# iosam3n register map
Registers are 32-bit, access not given, no defined reset value unless marked. A register's access mark holds for its fields unless they carry their own. Addresses are absolute; registers are grouped by the start of their names; [hi:lo] are bit positions; {n}, {i} and the like mark numbered series; 'fields as' and 'values as' point back to an identical list.

## ADC
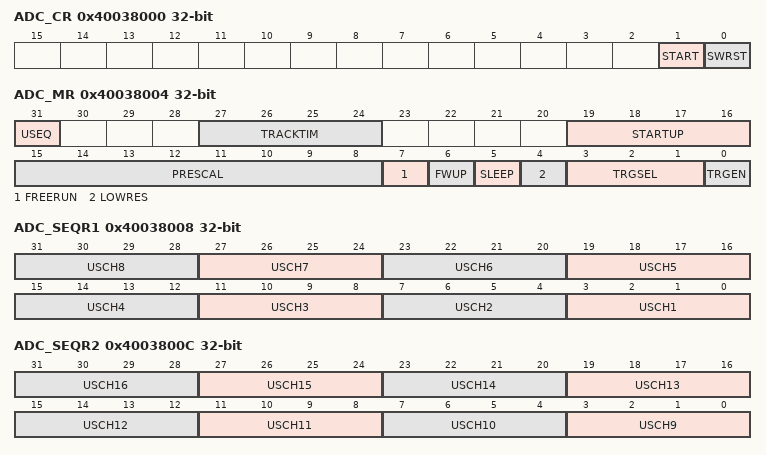
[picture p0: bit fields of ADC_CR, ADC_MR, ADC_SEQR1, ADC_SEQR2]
0x40038000 ADC_CR
  [1] START, [0] SWRST
0x40038004 ADC_MR
  [31] USEQ, [27:24] TRACKTIM, [19:16] STARTUP, [15:8] PRESCAL, [7] FREERUN, [6] FWUP, [5] SLEEP, [4] LOWRES, [3:1] TRGSEL, [0] TRGEN
0x40038008 ADC_SEQR1
  [4n-1:4n-4] USCH{n} (n=1..8)
0x4003800C ADC_SEQR2
  [4n-33:4n-36] USCH{n} (n=9..16)
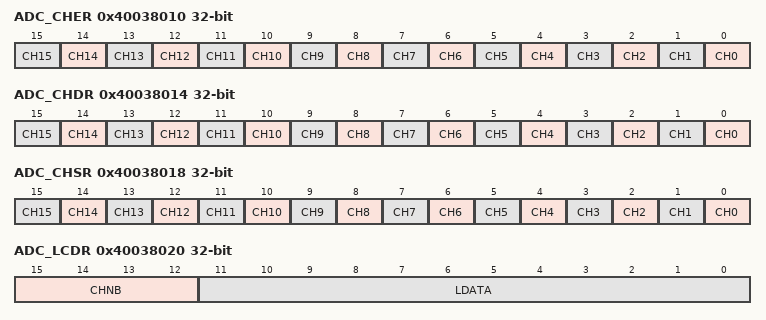
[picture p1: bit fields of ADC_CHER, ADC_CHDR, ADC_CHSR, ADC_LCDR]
0x40038010 ADC_CHER
  [n] CH{n} (n=0..15)
0x40038014 ADC_CHDR
  [n] CH{n} (n=0..15)
0x40038018 ADC_CHSR
  [n] CH{n} (n=0..15)
0x40038020 ADC_LCDR
  [15:12] CHNB, [11:0] LDATA
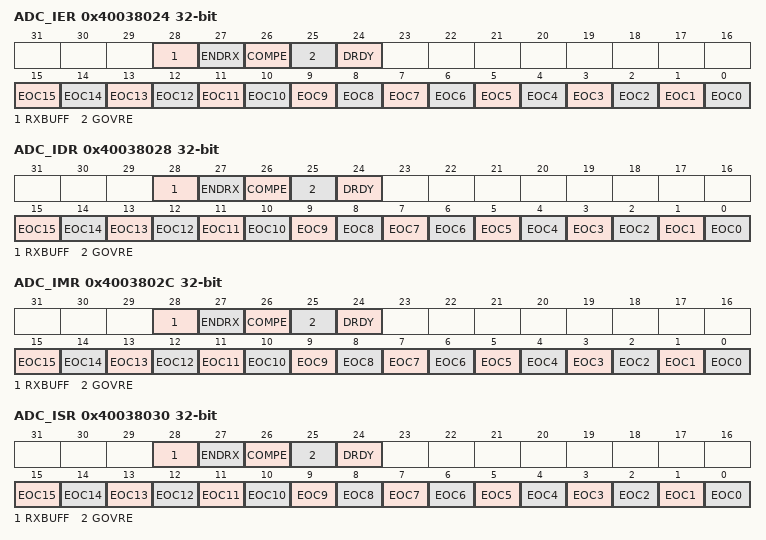
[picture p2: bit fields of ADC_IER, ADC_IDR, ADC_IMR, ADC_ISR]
0x40038024 ADC_IER
  [28] RXBUFF, [27] ENDRX, [26] COMPE, [25] GOVRE, [24] DRDY, [n] EOC{n} (n=0..15)
0x40038028 ADC_IDR
  fields as ADC_IER
0x4003802C ADC_IMR
  fields as ADC_IER
0x40038030 ADC_ISR
  fields as ADC_IER
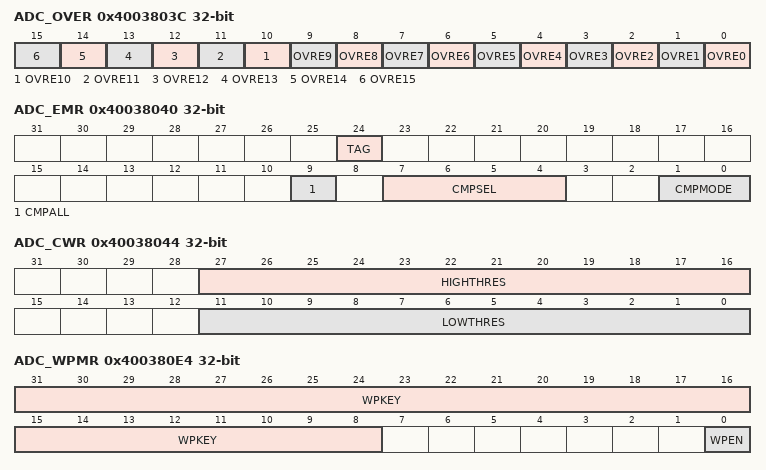
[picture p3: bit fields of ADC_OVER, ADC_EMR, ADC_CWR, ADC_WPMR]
0x4003803C ADC_OVER
  [n] OVRE{n} (n=0..15)
0x40038040 ADC_EMR
  [24] TAG, [9] CMPALL, [7:4] CMPSEL, [1:0] CMPMODE
0x40038044 ADC_CWR
  [27:16] HIGHTHRES, [11:0] LOWTHRES
{0x40038050+4i} ADC_CDR_{i} (i=0..15)
  [9:0] DATA
0x400380E4 ADC_WPMR
  [31:8] WPKEY, [0] WPEN
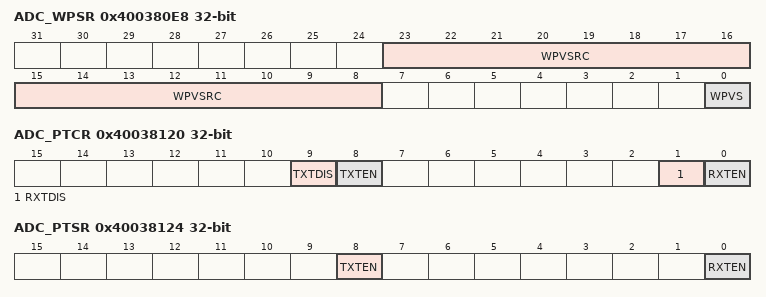
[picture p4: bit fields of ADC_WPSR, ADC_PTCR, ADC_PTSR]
0x400380E8 ADC_WPSR
  [23:8] WPVSRC, [0] WPVS
0x40038100 ADC_RPR
  [31:0] RXPTR
0x40038104 ADC_RCR
  [15:0] RXCTR
0x40038108 ADC_TPR
  [31:0] TXPTR
0x4003810C ADC_TCR
  [15:0] TXCTR
0x40038110 ADC_RNPR
  [31:0] RXNPTR
0x40038114 ADC_RNCR
  [15:0] RXNCTR
0x40038118 ADC_TNPR
  [31:0] TXNPTR
0x4003811C ADC_TNCR
  [15:0] TXNCTR
0x40038120 ADC_PTCR
  [9] TXTDIS, [8] TXTEN, [1] RXTDIS, [0] RXTEN
0x40038124 ADC_PTSR
  [8] TXTEN, [0] RXTEN

## DACC
0x4003C000 DACC_CR
  [0] SWRST
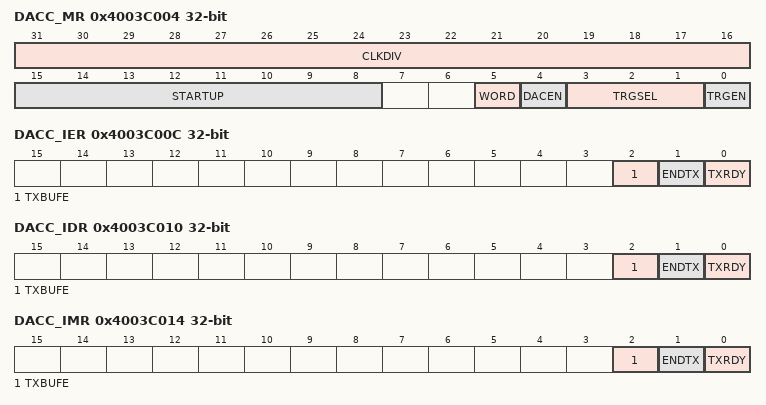
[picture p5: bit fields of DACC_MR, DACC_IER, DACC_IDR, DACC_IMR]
0x4003C004 DACC_MR
  [31:16] CLKDIV, [15:8] STARTUP, [5] WORD, [4] DACEN, [3:1] TRGSEL, [0] TRGEN
0x4003C008 DACC_CDR
  [31:0] DATA
0x4003C00C DACC_IER
  [2] TXBUFE, [1] ENDTX, [0] TXRDY
0x4003C010 DACC_IDR
  [2] TXBUFE, [1] ENDTX, [0] TXRDY
0x4003C014 DACC_IMR
  [2] TXBUFE, [1] ENDTX, [0] TXRDY
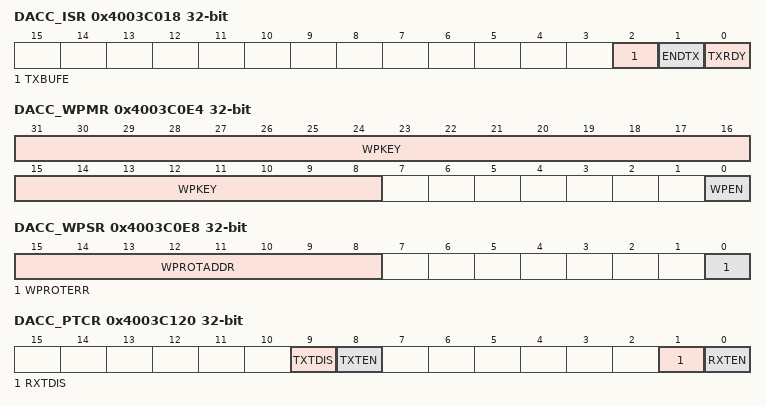
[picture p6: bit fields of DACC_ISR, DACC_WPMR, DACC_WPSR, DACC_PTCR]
0x4003C018 DACC_ISR
  [2] TXBUFE, [1] ENDTX, [0] TXRDY
0x4003C0E4 DACC_WPMR
  [31:8] WPKEY, [0] WPEN
0x4003C0E8 DACC_WPSR
  [15:8] WPROTADDR, [0] WPROTERR
0x4003C100 DACC_RPR
  [31:0] RXPTR
0x4003C104 DACC_RCR
  [15:0] RXCTR
0x4003C108 DACC_TPR
  [31:0] TXPTR
0x4003C10C DACC_TCR
  [15:0] TXCTR
0x4003C110 DACC_RNPR
  [31:0] RXNPTR
0x4003C114 DACC_RNCR
  [15:0] RXNCTR
0x4003C118 DACC_TNPR
  [31:0] TXNPTR
0x4003C11C DACC_TNCR
  [15:0] TXNCTR
0x4003C120 DACC_PTCR
  [9] TXTDIS, [8] TXTEN, [1] RXTDIS, [0] RXTEN
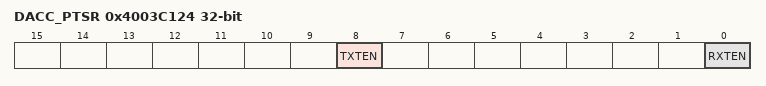
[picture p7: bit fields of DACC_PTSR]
0x4003C124 DACC_PTSR
  [8] TXTEN, [0] RXTEN

## MATRIX
{0x400E0200+4i} MATRIX_MCFG_{i} (i=0..2)
  [2:0] ULBT
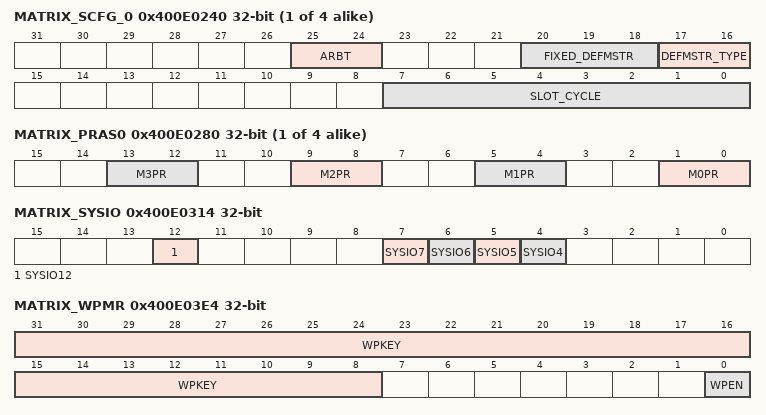
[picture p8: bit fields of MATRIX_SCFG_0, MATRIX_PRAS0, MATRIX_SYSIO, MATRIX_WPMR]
{0x400E0240+4i} MATRIX_SCFG_{i} (i=0..3)
  [25:24] ARBT, [20:18] FIXED_DEFMSTR, [17:16] DEFMSTR_TYPE, [7:0] SLOT_CYCLE
{0x400E0280+8i} MATRIX_PRAS{i} (i=0..3)
  [4n+1:4n] M{n}PR (n=0..3)
0x400E0314 MATRIX_SYSIO
  [12] SYSIO12, [n] SYSIO{n} (n=4..7)
0x400E03E4 MATRIX_WPMR
  [31:8] WPKEY, [0] WPEN
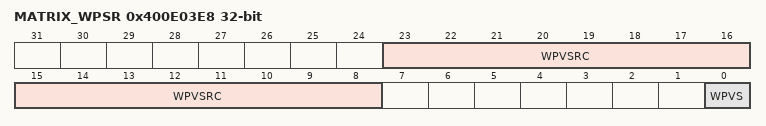
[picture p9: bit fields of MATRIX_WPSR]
0x400E03E8 MATRIX_WPSR
  [23:8] WPVSRC, [0] WPVS

## PMC
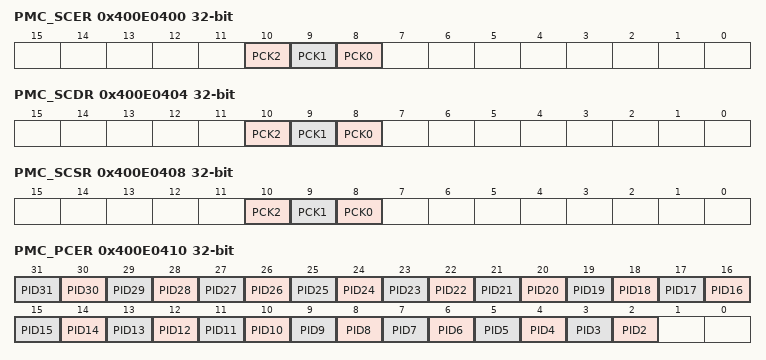
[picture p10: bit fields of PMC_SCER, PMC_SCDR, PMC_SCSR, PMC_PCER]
0x400E0400 PMC_SCER
  [10] PCK2, [9] PCK1, [8] PCK0
0x400E0404 PMC_SCDR
  [10] PCK2, [9] PCK1, [8] PCK0
0x400E0408 PMC_SCSR
  [10] PCK2, [9] PCK1, [8] PCK0
0x400E0410 PMC_PCER
  [n] PID{n} (n=2..31)
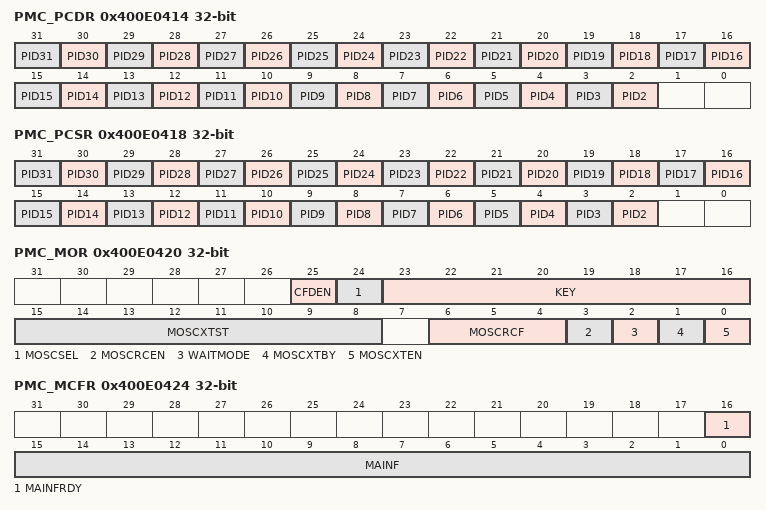
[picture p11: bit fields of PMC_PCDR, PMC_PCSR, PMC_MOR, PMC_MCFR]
0x400E0414 PMC_PCDR
  [n] PID{n} (n=2..31)
0x400E0418 PMC_PCSR
  [n] PID{n} (n=2..31)
0x400E0420 PMC_MOR
  [25] CFDEN, [24] MOSCSEL, [23:16] KEY, [15:8] MOSCXTST, [6:4] MOSCRCF, [3] MOSCRCEN, [2] WAITMODE, [1] MOSCXTBY, [0] MOSCXTEN
0x400E0424 PMC_MCFR
  [16] MAINFRDY, [15:0] MAINF
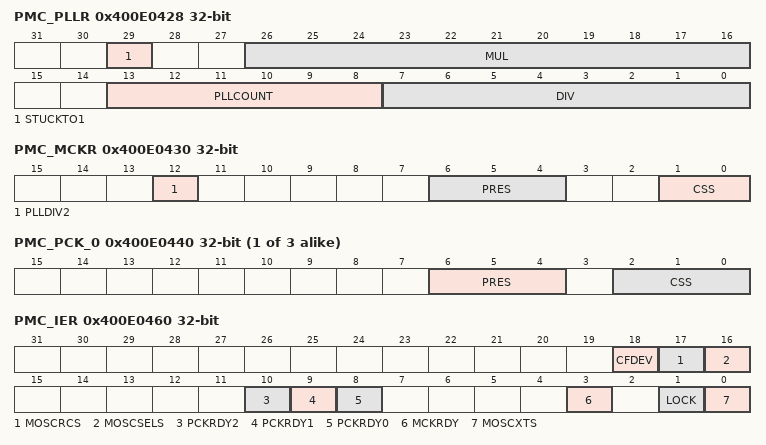
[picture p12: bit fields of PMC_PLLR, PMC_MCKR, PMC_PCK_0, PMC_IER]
0x400E0428 PMC_PLLR
  [29] STUCKTO1, [26:16] MUL, [13:8] PLLCOUNT, [7:0] DIV
0x400E0430 PMC_MCKR
  [12] PLLDIV2, [6:4] PRES, [1:0] CSS
{0x400E0440+4i} PMC_PCK_{i} (i=0..2)
  [6:4] PRES, [2:0] CSS
0x400E0460 PMC_IER
  [18] CFDEV, [17] MOSCRCS, [16] MOSCSELS, [10] PCKRDY2, [9] PCKRDY1, [8] PCKRDY0, [3] MCKRDY, [1] LOCK, [0] MOSCXTS
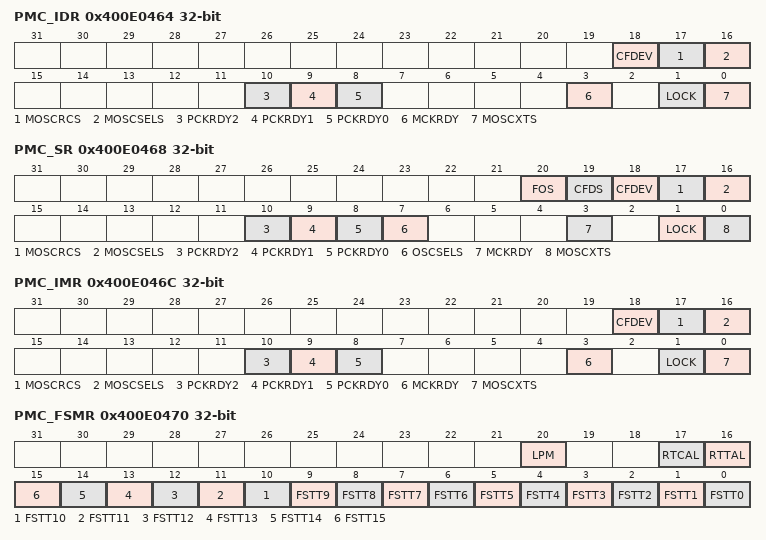
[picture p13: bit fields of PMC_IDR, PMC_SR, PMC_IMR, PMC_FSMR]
0x400E0464 PMC_IDR
  fields as PMC_IER
0x400E0468 PMC_SR
  [20] FOS, [19] CFDS, [18] CFDEV, [17] MOSCRCS, [16] MOSCSELS, [10] PCKRDY2, [9] PCKRDY1, [8] PCKRDY0, [7] OSCSELS, [3] MCKRDY, [1] LOCK, [0] MOSCXTS
0x400E046C PMC_IMR
  fields as PMC_IER
0x400E0470 PMC_FSMR
  [20] LPM, [17] RTCAL, [16] RTTAL, [n] FSTT{n} (n=0..15)
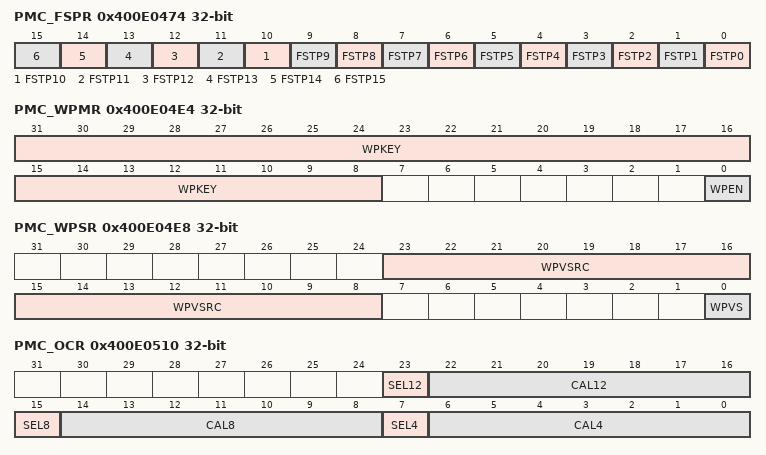
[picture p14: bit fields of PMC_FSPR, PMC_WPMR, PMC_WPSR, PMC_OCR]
0x400E0474 PMC_FSPR
  [n] FSTP{n} (n=0..15)
0x400E0478 PMC_FOCR
  [0] FOCLR
0x400E04E4 PMC_WPMR
  [31:8] WPKEY, [0] WPEN
0x400E04E8 PMC_WPSR
  [23:8] WPVSRC, [0] WPVS
0x400E0510 PMC_OCR
  [23] SEL12, [22:16] CAL12, [15] SEL8, [14:8] CAL8, [7] SEL4, [6:0] CAL4
